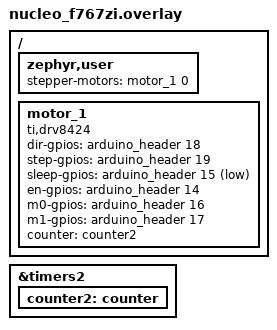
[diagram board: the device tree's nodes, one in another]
/*
 * Copyright (c) 2024 Navimatix GmbH
 * SPDX-License-Identifier: Apache-2.0
 */

 #include <zephyr/dt-bindings/gpio/gpio.h>

/ {
	 zephyr,user {
		 stepper-motors = <&motor_1 0>;
	 };
};

/ {

	 motor_1: motor_1 {
		 status = "okay";
		 compatible = "ti,drv8424";


		 dir-gpios = <&arduino_header 18 0>; /* D12 */
		 step-gpios = <&arduino_header 19 0>; /* D13 */
		 sleep-gpios = <&arduino_header 15 GPIO_ACTIVE_LOW>; /* D9 */
		 en-gpios  = <&arduino_header 14 0>; /* D8 */
		 m0-gpios = <&arduino_header 16 0>;
		 m1-gpios = <&arduino_header 17 0>;
		 counter = <&counter2>;

		 #address-cells = <1>;
		 #size-cells = <0>;
		 #stepper-motor-cells = <0>;

	 };
};

&timers2 {
	 status = "okay";
	 counter2: counter {
		 status = "okay";
	 };
};
